# RT58X register map
Series: ARMv8-M Mainline; File version: 1.0
CPU: CM3 r0p0, little endian, MPU, no FPU, VTOR, 3 interrupt priority bits
Registers are 32-bit, read-write, reset 0x0 unless marked. A register's access mark holds for its fields unless they carry their own. Offsets are from the block's base; [hi:lo] are bit positions; {n}, {i} and the like mark numbered series; 'fields as' and 'values as' point back to an identical list.

## DMA0 — DMA0 Register block
Base 0xC0000000
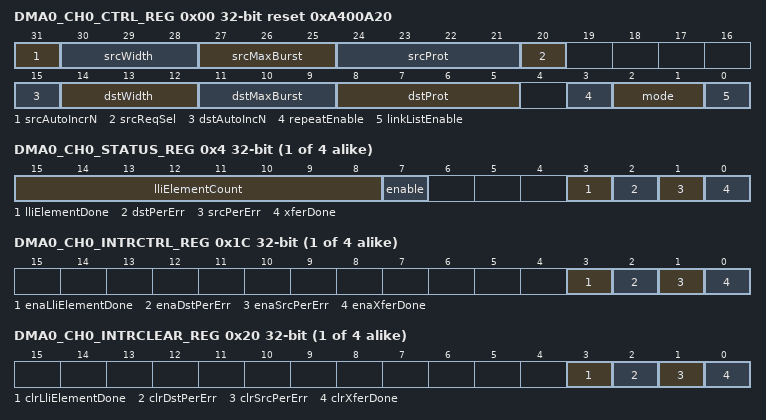
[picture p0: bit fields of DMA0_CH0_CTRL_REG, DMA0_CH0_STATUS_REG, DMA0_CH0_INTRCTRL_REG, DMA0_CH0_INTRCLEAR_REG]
0x00 DMA0_CH0_CTRL_REG reset 0xA400A20 — dma0 ch0 ctrl
  [31] srcAutoIncrN — 0: Increment the source address 1: Do not increment the source addres
    0=B_31 (0: Increment the source address 1: Do not increment the source addres)
  [30:28] srcWidth — Width of Source device in terms of the AHB signal HSIZE: 0: 8-bit device 1: 16-bit device 2: 32-bit device All others reserved.
    0=B_28_to_30 (Width of Source device in terms of the AHB signal HSIZE: 0: 8-bit device 1: 16-bit device 2: 32-bit device All others reserved.)
  [27:25] srcMaxBurst — Maximum Source Burst according to AHB signal HBURST: 0: No bursting, single transfers only 1: Reserved, not supported 2: 4-beat Wrapping Burst 3: 4-beat Incrementing Burst 4: 8-beat Wrapping Burst 5: 8-beat Incrementing Burst 6: reserved, FIFO size is 8x32 7: reserved, FIFO size is 8x32
    0=B_25_to_27 (Maximum Source Burst according to AHB signal HBURST: 0: No bursting, single transfers only 1: Reserved, not supported 2: 4-beat Wrapping Burst 3: 4-beat Incrementing Burst 4: 8-beat Wrapping Burst 5: 8-beat Incrementing Burst 6: reserved, FIFO size is 8x32 7: reserved, FIFO size is 8x32)
  [24:21] srcProt — Source Protection coding according to AHB signal HPROT: HPROT[3]: 1 = cacheable, 0 = non-cacheable HPROT[2]: 1 = bufferable, 0 = non-bufferable HPROT[1]: 1 = Priveleged Access, 0 = User Access HPROT[0]: 1 = Opcode Fetch, 0 = Data Access
    0=B_21_to_24 (Source Protection coding according to AHB signal HPROT: HPROT[3]: 1 = cacheable, 0 = non-cacheable HPROT[2]: 1 = bufferable, 0 = non-bufferable HPROT[1]: 1 = Priveleged Access, 0 = User Access HPROT[0]: 1 = Opcode Fetch, 0 = Data Access)
  [20] srcReqSel — Select peripheral source request of RX: 0: burst request 1: single request
    0=B_20 (Select peripheral source request of RX: 0: burst request 1: single request)
  [15] dstAutoIncN — 0: Increment the destination address 1: Do not increment the destination address
    0=B_15 (0: Increment the destination address 1: Do not increment the destination address)
  [14:12] dstWidth — Width of Destination device in terms of the AHB parameter HSIZE: 0: 8-bit device 1: 16-bit device 2: 32-bit device All others reserved.
    0=B_12_to_14 (Width of Destination device in terms of the AHB parameter HSIZE: 0: 8-bit device 1: 16-bit device 2: 32-bit device All others reserved.)
  [11:9] dstMaxBurst — Maximum Destination Burst according to AHB signal HBURST: 0: No bursting, single transfers 1: Reserved, not supported 2: 4-beat Wrapping Burst 3: 4-beat Incrementing Burst 4: 8-beat Wrapping Burst 5: 8-beat Incrementing Burst 6: reserved, FIFO size is 8x32 7: reserved, FIFO size is 8x32
    0=B_9_to_11 (Maximum Destination Burst according to AHB signal HBURST: 0: No bursting, single transfers 1: Reserved, not supported 2: 4-beat Wrapping Burst 3: 4-beat Incrementing Burst 4: 8-beat Wrapping Burst 5: 8-beat Incrementing Burst 6: reserved, FIFO size is 8x32 7: reserved, FIFO size is 8x32)
  [8:5] dstProt — Destination Protection coding according to AHB signal HPROT: HPROT[3]: 1 = cacheable, 0 = non-cacheable HPROT[2]: 1 = bufferable, 0 = non-bufferable HPROT[1]: 1 = Priveleged Access, 0 = User Access HPROT[0]: 1 = Opcode Fetch, 0 = Data Access
    0=B_5_to_8 (Destination Protection coding according to AHB signal HPROT: HPROT[3]: 1 = cacheable, 0 = non-cacheable HPROT[2]: 1 = bufferable, 0 = non-bufferable HPROT[1]: 1 = Priveleged Access, 0 = User Access HPROT[0]: 1 = Opcode Fetch, 0 = Data Access)
  [3] repeatEnable — 0: transfer is not repeated 1: transfer of XferLength bytes is repeated according to the value in the RepeatVal register
    0=B_3 (0: transfer is not repeated 1: transfer of XferLength bytes is repeated according to the value in the RepeatVal register)
  [2:1] mode — Modes: 0: Source Memory to Destination Memory 1: Source Memory to Destination Peripheral 2: Source Peripheral to Destination Memory 3: Source Peripheral to Destination Peripheral
    0=B_1_to_2 (Modes: 0: Source Memory to Destination Memory 1: Source Memory to Destination Peripheral 2: Source Peripheral to Destination Memory 3: Source Peripheral to Destination Peripheral)
  [0] linkListEnable — 0: use registers; no linked lists 1: enable the linked list pointers
    0=B_0 (0: use registers; no linked lists 1: enable the linked list pointers)
{0x4+0x100*i} DMA0_CH{i}_STATUS_REG ro (i=0..3) — dma0 ch{i} status
  [15:8] lliElementCount — 8-bit rollover counter that tracks the number of completed linked list transfers. This counter is reset upon a write to the Enable register.
    0=B_8_to_15 (8-bit rollover counter that tracks the number of completed linked list transfers. This counter is reset upon a write to the Enable register.)
  [7] enable — 0: not enabled 1: enabled
    0=B_7 (0: not enabled 1: enabled)
  [3] lliElementDone — 0: the DMA controller has not processed any list elements in LLI mode since the last DMAStatus Register read This bit is automatically cleared upon reading the DMAStatus Register 1: the DMA controller has processed at least one list element in LLI mode since the last DMAStatus Register read
    0=B_3 (0: the DMA controller has not processed any list elements in LLI mode since the last DMAStatus Register read This bit is automatically cleared upon reading the DMAStatus Register 1: the DMA controller has processed at least one list element in LLI mode since the last DMAStatus Register read)
  [2] dstPerErr — Destination peripheral HRESP=ERROR; this bit is cleared upon writing a 0 to the Enable Register to disable the DMA controller operation.
    0=B_2 (Destination peripheral HRESP=ERROR; this bit is cleared upon writing a 0 to the Enable Register to disable the DMA controller operation.)
  [1] srcPerErr — Source peripheral HRESP=ERROR; this bit is cleared upon writing a 0 to the Enable Register to disable the DMA controller operation.
    0=B_1 (Source peripheral HRESP=ERROR; this bit is cleared upon writing a 0 to the Enable Register to disable the DMA controller operation.)
  [0] xferDone — Transfer complete; this bit is cleared upon writing a 0 to the Enable Register to disable the DMA controller operation.
    0=B_0 (Transfer complete; this bit is cleared upon writing a 0 to the Enable Register to disable the DMA controller operation.)
{0x8+0x100*i} DMA0_CH{i}_SRC_REG (i=0..3) — Source Address Descriptor Note: Must agree with srcWidth field of Control Register. Note: If linkListEnable = 1, this register is interpreted as the initial linked list pointer.
{0xC+0x100*i} DMA0_CH{i}_DEST_REG (i=0..3) — Destination Address Descriptor Note: Must agree with dstWidth field of Control Register.
{0x10+0x100*i} DMA0_CH{i}_XFER_LEN_REG (i=0..3) — Transfer length in bytes Note: Must agree with dstWidth field of Control Register.
{0x14+0x100*i} DMA0_CH{i}_CURSRCADDR_REG ro (i=0..3) — Current source address
{0x18+0x100*i} DMA0_CH{i}_CURDESTADDR_REG ro (i=0..3) — Current destination address
{0x1C+0x100*i} DMA0_CH{i}_INTRCTRL_REG (i=0..3) — dma0 ch{i} intrctrl
  [3] enaLliElementDone — Enable linked list element complete interrupt
    0=B_3 (Enable linked list element complete interrupt)
  [2] enaDstPerErr — Enable Destination peripheral HRESP=ERROR interrupt
    0=B_2 (Enable Destination peripheral HRESP=ERROR interrupt)
  [1] enaSrcPerErr — Enable Source peripheral HRESP=ERROR interrupt
    0=B_1 (Enable Source peripheral HRESP=ERROR interrupt)
  [0] enaXferDone — Enable Transfer complete interrupt
    0=B_0 (Enable Transfer complete interrupt)
{0x20+0x100*i} DMA0_CH{i}_INTRCLEAR_REG (i=0..3) — dma0 ch{i} intrclear
  [3] clrLliElementDone wo — Write 1 to clear linked list element complete interrupt
    0=B_3 (Write 1 to clear linked list element complete interrupt)
  [2] clrDstPerErr wo — Write 1 to clear Destination peripheral HRESP=ERROR interrupt
    0=B_2 (Write 1 to clear Destination peripheral HRESP=ERROR interrupt)
  [1] clrSrcPerErr wo — Write 1 to clear Source peripheral HRESP=ERROR interrupt
    0=B_1 (Write 1 to clear Source peripheral HRESP=ERROR interrupt)
  [0] clrXferDone wo — Write 1 to clear Transfer complete interrupt
    0=B_0 (Write 1 to clear Transfer complete interrupt)
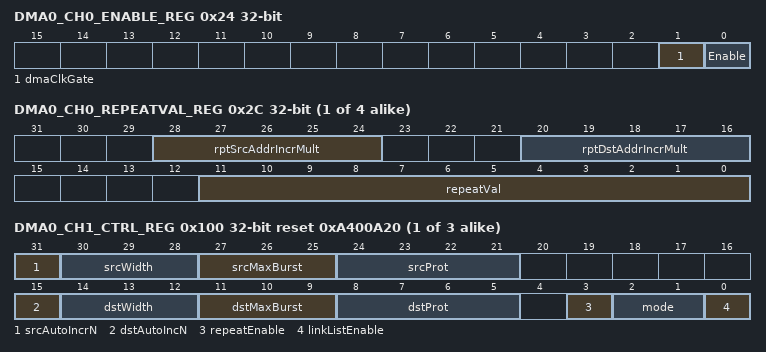
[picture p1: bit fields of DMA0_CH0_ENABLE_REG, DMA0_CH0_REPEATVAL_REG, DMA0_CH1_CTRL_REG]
0x24 DMA0_CH0_ENABLE_REG — dma0 ch0 enable
  [1] dmaClkGate — 0: DMA master clock gating Disable 1: DMA master clock gating Enable
    0=B_1 (0: DMA master clock gating Disable 1: DMA master clock gating Enable)
  [0] Enable — 0: DMA Disable 1: DMA Enable
    0=B_0 (0: DMA Disable 1: DMA Enable)
{0x28+0x100*i} DMA0_CH{i}_LLINEXTPTR_REG ro (i=0..3) — Displays the current LLI Next Pointer when DMA transfer is under link-list control (linkListEnable = 1). When link-list control is disabled, this register is read as 0.
{0x2C+0x100*i} DMA0_CH{i}_REPEATVAL_REG (i=0..3) — dma0 ch{i} repeatval
  [28:24] rptSrcAddrIncrMult — Allowed values: 0, 1, 2, 4, 8, 16 If the repeatEnable bit (in the DMACtrl register) is 1, this subfield determines how the source address is incremented after each iteration of the repeated transfer. rptSrcAddrIncrMult is rightshifted by srcWidth to get the increment value. For example, if srcWidth = 3’b001 and rptSrcAddrIncrMult = 16, the source address will be incremented by 32 after each iteration. A value of 0 in this subfield has the effect of not incrementing the base source address between iterations.
    0=B_24_to_28 (Allowed values: 0, 1, 2, 4, 8, 16 If the repeatEnable bit (in the DMACtrl register) is 1, this subfield determines how the source address is incremented after each iteration of the repeated transfer. rptSrcAddrIncrMult is rightshifted by srcWidth to get the increment value. For example, if srcWidth = 3’b001 and rptSrcAddrIncrMult = 16, the source address will be incremented by 32 after each iteration. A value of 0 in this subfield has the effect of not incrementing the base source address between iterations.)
  [20:16] rptDstAddrIncrMult — Allowed values: 0, 1, 2, 4, 8, 16 If the repeatEnable bit (in the DMACtrl register) is 1, this subfield determines how the destination address is incremented after each iteration of the repeated transfer. rptDstAddrIncrMult is right-shifted by dstWidth to get the increment value. For example, if dstWidth = 3’b010 and rptDstAddrIncrMult = 4, the destination address will be incremented by 16 after each iteration. A value of 0 in this subfield has the effect of not incrementing the base destination address between iterations.
    0=B_16_to_20 (Allowed values: 0, 1, 2, 4, 8, 16 If the repeatEnable bit (in the DMACtrl register) is 1, this subfield determines how the destination address is incremented after each iteration of the repeated transfer. rptDstAddrIncrMult is right-shifted by dstWidth to get the increment value. For example, if dstWidth = 3’b010 and rptDstAddrIncrMult = 4, the destination address will be incremented by 16 after each iteration. A value of 0 in this subfield has the effect of not incrementing the base destination address between iterations.)
  [11:0] repeatVal — If the repeatEnable bit (in the DMACtrl register) is 1, this subfield determines the number of times a given DMA transfer of XferLength bytes is repeated. repeatVal=0 means that the requested transfer will execute once, and will not be repeated. A maximum value of 4095 means that the requested transfer will be executed 4096 times.
0x30 DMA0_CH0_REPEATSTATUS_REG ro — dma0 ch0 repeatstatus
  [11:0] RepeatStatus — If the repeatEnable bit (in the DMACtrl register) is 1, this field represents a current status of the down-counter that keeps track of the number of times a DMA transfer is repeated. RepeatStatus will start with the value in RepeatVal and will be decremented by 1 upon completion of the transfer of XferLength bytes until RepeatStatus is 0. If the repeatEnable bit is 0, this field has no meaning and can be ignored.
{0x0+0x100*i} DMA0_CH{i}_CTRL_REG reset 0xA400A20 (i=1..3) — dma0 ch{i} ctrl
  [31] srcAutoIncrN — 0: Increment the source address 1: Do not increment the source addres
    values as DMA0_CH0_CTRL_REG.srcAutoIncrN
  [30:28] srcWidth — Width of Source device in terms of the AHB signal HSIZE: 0: 8-bit device 1: 16-bit device 2: 32-bit device All others reserved.
    values as DMA0_CH0_CTRL_REG.srcWidth
  [27:25] srcMaxBurst — Maximum Source Burst according to AHB signal HBURST: 0: No bursting, single transfers only 1: Reserved, not supported 2: 4-beat Wrapping Burst 3: 4-beat Incrementing Burst 4: 8-beat Wrapping Burst 5: 8-beat Incrementing Burst 6: reserved, FIFO size is 8x32 7: reserved, FIFO size is 8x32
    values as DMA0_CH0_CTRL_REG.srcMaxBurst
  [24:21] srcProt — Source Protection coding according to AHB signal HPROT: HPROT[3]: 1 = cacheable, 0 = non-cacheable HPROT[2]: 1 = bufferable, 0 = non-bufferable HPROT[1]: 1 = Priveleged Access, 0 = User Access HPROT[0]: 1 = Opcode Fetch, 0 = Data Access
    values as DMA0_CH0_CTRL_REG.srcProt
  [15] dstAutoIncN — 1 = Do not increment the destination address 0 = Increment the destination address
    0=B_15 (1 = Do not increment the destination address 0 = Increment the destination address)
  [14:12] dstWidth — Width of Destination device in terms of the AHB parameter HSIZE: 0: 8-bit device 1: 16-bit device 2: 32-bit device All others reserved.
    values as DMA0_CH0_CTRL_REG.dstWidth
  [11:9] dstMaxBurst — Maximum Destination Burst according to AHB signal HBURST: 0: No bursting, single transfers 1: Reserved, not supported 2: 4-beat Wrapping Burst 3: 4-beat Incrementing Burst 4: 8-beat Wrapping Burst 5: 8-beat Incrementing Burst 6: reserved, FIFO size is 8x32 7: reserved, FIFO size is 8x32
    values as DMA0_CH0_CTRL_REG.dstMaxBurst
  [8:5] dstProt — Destination Protection coding according to AHB signal HPROT: HPROT[3]: 1 = cacheable, 0 = non-cacheable HPROT[2]: 1 = bufferable, 0 = non-bufferable HPROT[1]: 1 = Priveleged Access, 0 = User Access HPROT[0]: 1 = Opcode Fetch, 0 = Data Access
    values as DMA0_CH0_CTRL_REG.dstProt
  [3] repeatEnable — 0: transfer is not repeated 1: transfer of XferLength bytes is repeated according to the value in the RepeatVal register
    values as DMA0_CH0_CTRL_REG.repeatEnable
  [2:1] mode — Modes: 0: Source Memory to Destination Memory 1: Source Memory to Destination Peripheral 2: Source Peripheral to Destination Memory 3: Source Peripheral to Destination Peripheral
    values as DMA0_CH0_CTRL_REG.mode
  [0] linkListEnable — 0: use registers; no linked lists 1: enable the linked list pointers
    values as DMA0_CH0_CTRL_REG.linkListEnable
{0x24+0x100*i} DMA0_CH{i}_ENABLE_REG (i=1..3) — dma0 ch{i} enable
  [0] Enable — 0: DMA Disable 1: DMA Enable
    0=B_0 (0: DMA Disable 1: DMA Enable)
{0x30+0x100*i} DMA0_CH{i}_REPEATSTATUS_REG ro (i=1..3) — dma0 ch{i} repeatstatus
  [9:0] RepeatStatus — If the repeatEnable bit (in the DMACtrl register) is 1, this field represents a current status of the down-counter that keeps track of the number of times a DMA transfer is repeated. RepeatStatus will start with the value in RepeatVal and will be decremented by 1 upon completion of the transfer of XferLength bytes until RepeatStatus is 0. If the repeatEnable bit is 0, this field has no meaning and can be ignored.
